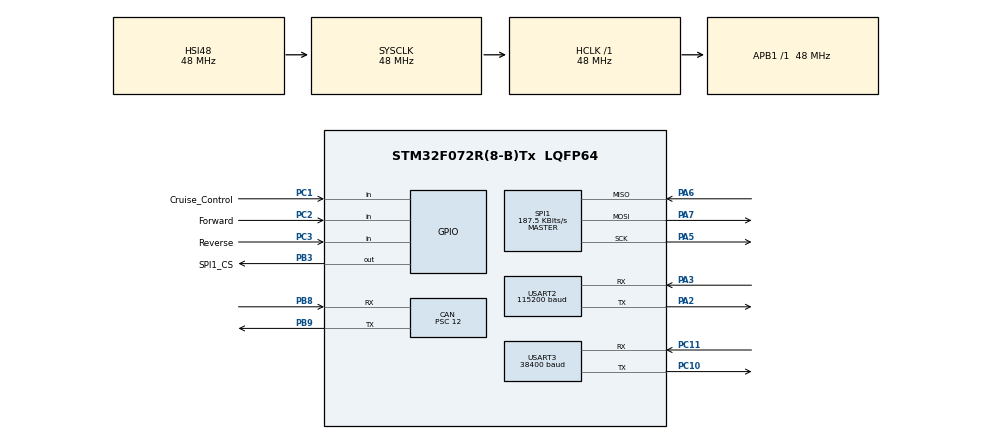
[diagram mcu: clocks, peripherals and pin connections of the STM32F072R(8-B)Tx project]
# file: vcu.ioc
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CAN.BS1=CAN_BS1_13TQ
CAN.BS2=CAN_BS2_2TQ
CAN.CalculateBaudRate=250000
CAN.CalculateTimeBit=4000
CAN.CalculateTimeQuantum=250.0
CAN.Prescaler=12
Mcu.Family=STM32F0
Mcu.Name=STM32F072R(8-B)Tx
Mcu.Package=LQFP64
PA2.Mode=Asynchronous
PA2.Signal=USART2_TX
PA3.Mode=Asynchronous
PA3.Signal=USART2_RX
PA5.Mode=Full_Duplex_Master
PA5.Signal=SPI1_SCK
PA6.Mode=Full_Duplex_Master
PA6.Signal=SPI1_MISO
PA7.Mode=Full_Duplex_Master
PA7.Signal=SPI1_MOSI
PB3.GPIO_Label=SPI1_CS
PB3.Signal=GPIO_Output
PB8.Mode=CAN_Activate
PB8.Signal=CAN_RX
PB9.Mode=CAN_Activate
PB9.Signal=CAN_TX
PC1.GPIO_Label=Cruise_Control
PC1.GPIO_PuPd=GPIO_PULLUP
PC1.Signal=GPIO_Input
PC10.Mode=Asynchronous
PC10.Signal=USART3_TX
PC11.Mode=Asynchronous
PC11.Signal=USART3_RX
PC2.GPIO_Label=Forward
PC2.GPIO_PuPd=GPIO_PULLUP
PC2.Signal=GPIO_Input
PC3.GPIO_Label=Reverse
PC3.GPIO_PuPd=GPIO_PULLUP
PC3.Signal=GPIO_Input
PF0-OSC_IN.Mode=HSE-External-Oscillator
PF0-OSC_IN.Signal=RCC_OSC_IN
PF1-OSC_OUT.Mode=HSE-External-Oscillator
PF1-OSC_OUT.Signal=RCC_OSC_OUT
ProjectManager.HeapSize=0x200
ProjectManager.StackSize=0x400
ProjectManager.TargetToolchain=STM32CubeIDE
RCC.AHBFreq_Value=48000000
RCC.APB1Freq_Value=48000000
RCC.APB1TimFreq_Value=48000000
RCC.HCLKFreq_Value=48000000
RCC.PLLSourceVirtual=RCC_PLLSOURCE_HSI48
RCC.SYSCLKFreq_VALUE=48000000
RCC.SYSCLKSource=RCC_SYSCLKSOURCE_HSI48
SPI1.BaudRatePrescaler=SPI_BAUDRATEPRESCALER_256
SPI1.CLKPolarity=SPI_POLARITY_LOW
SPI1.CalculateBaudRate=187.5 KBits/s
SPI1.DataSize=SPI_DATASIZE_8BIT
SPI1.Direction=SPI_DIRECTION_2LINES
SPI1.Mode=SPI_MODE_MASTER
SPI1.VirtualType=VM_MASTER
TIM16.Period=249
TIM16.Prescaler=47999
TIM6.Period=499
TIM6.Prescaler=47
TIM7.Period=39
TIM7.Prescaler=47999
USART2.BaudRate=115200
USART2.VirtualMode-Asynchronous=VM_ASYNC
USART3.BaudRate=38400
USART3.SwapParam=ADVFEATURE_SWAP_DISABLE
USART3.VirtualMode-Asynchronous=VM_ASYNC
VP_TIM16_VS_ClockSourceINT.Mode=Enable_Timer
VP_TIM3_VS_ClockSourceINT.Mode=Internal
VP_TIM6_VS_ClockSourceINT.Mode=Enable_Timer
VP_TIM7_VS_ClockSourceINT.Mode=Enable_Timer
board=custom

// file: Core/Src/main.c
/* USER CODE BEGIN Header */
/**
  ******************************************************************************
  * @file           : main.c
  * @brief          : Main program body
  ******************************************************************************
  * @attention
  *
  * Copyright (c) 2023 STMicroelectronics.
  * All rights reserved.
  *
  * This software is licensed under terms that can be found in the LICENSE file
  * in the root directory of this software component.
  * If no LICENSE file comes with this software, it is provided AS-IS.
  *
  ******************************************************************************
  */
/* USER CODE END Header */
#include "main.h"

/* USER CODE BEGIN Includes */
#include "run.h"
/* USER CODE END Includes */

CAN_HandleTypeDef hcan;

SPI_HandleTypeDef hspi1;

TIM_HandleTypeDef htim3;
TIM_HandleTypeDef htim6;
TIM_HandleTypeDef htim7;
TIM_HandleTypeDef htim16;

UART_HandleTypeDef huart2;
UART_HandleTypeDef huart3;

void SystemClock_Config(void);
static void MX_GPIO_Init(void);
static void MX_SPI1_Init(void);
static void MX_USART2_UART_Init(void);
static void MX_CAN_Init(void);
static void MX_TIM3_Init(void);
static void MX_USART3_UART_Init(void);
static void MX_TIM7_Init(void);
static void MX_TIM6_Init(void);
static void MX_TIM16_Init(void);

int main(void)
{

  /* MCU Configuration--------------------------------------------------------*/

  /* Reset of all peripherals, Initializes the Flash interface and the Systick. */
  HAL_Init();

  /* Configure the system clock */
  SystemClock_Config();

  /* Initialize all configured peripherals */
  MX_GPIO_Init();
  MX_SPI1_Init();
  MX_USART2_UART_Init();
  MX_CAN_Init();
  MX_TIM3_Init();
  MX_USART3_UART_Init();
  MX_TIM7_Init();
  MX_TIM6_Init();
  MX_TIM16_Init();
  /* USER CODE BEGIN 2 */
  run(&htim3, &hcan, &hspi1, &huart2, &huart3, &htim7, &htim6, &htim16);
  /* USER CODE END 2 */

  /* Infinite loop */
  while (1)
  {

  }
}

void SystemClock_Config(void)
{
  RCC_OscInitTypeDef RCC_OscInitStruct = {0};
  RCC_ClkInitTypeDef RCC_ClkInitStruct = {0};
  RCC_PeriphCLKInitTypeDef PeriphClkInit = {0};

  /** Initializes the RCC Oscillators according to the specified parameters
  * in the RCC_OscInitTypeDef structure.
  */
  RCC_OscInitStruct.OscillatorType = RCC_OSCILLATORTYPE_HSI48;
  RCC_OscInitStruct.HSI48State = RCC_HSI48_ON;
  RCC_OscInitStruct.PLL.PLLState = RCC_PLL_NONE;
  if (HAL_RCC_OscConfig(&RCC_OscInitStruct) != HAL_OK)
  {
    Error_Handler();
  }

  /** Initializes the CPU, AHB and APB buses clocks
  */
  RCC_ClkInitStruct.ClockType = RCC_CLOCKTYPE_HCLK|RCC_CLOCKTYPE_SYSCLK
                              |RCC_CLOCKTYPE_PCLK1;
  RCC_ClkInitStruct.SYSCLKSource = RCC_SYSCLKSOURCE_HSI48;
  RCC_ClkInitStruct.AHBCLKDivider = RCC_SYSCLK_DIV1;
  RCC_ClkInitStruct.APB1CLKDivider = RCC_HCLK_DIV1;

  if (HAL_RCC_ClockConfig(&RCC_ClkInitStruct, FLASH_LATENCY_1) != HAL_OK)
  {
    Error_Handler();
  }
  PeriphClkInit.PeriphClockSelection = RCC_PERIPHCLK_USART2;
  PeriphClkInit.Usart2ClockSelection = RCC_USART2CLKSOURCE_PCLK1;
  if (HAL_RCCEx_PeriphCLKConfig(&PeriphClkInit) != HAL_OK)
  {
    Error_Handler();
  }
}

static void MX_CAN_Init(void)
{

  hcan.Instance = CAN;
  hcan.Init.Prescaler = 12;
  hcan.Init.Mode = CAN_MODE_NORMAL;
  hcan.Init.SyncJumpWidth = CAN_SJW_1TQ;
  hcan.Init.TimeSeg1 = CAN_BS1_13TQ;
  hcan.Init.TimeSeg2 = CAN_BS2_2TQ;
  hcan.Init.TimeTriggeredMode = DISABLE;
  hcan.Init.AutoBusOff = DISABLE;
  hcan.Init.AutoWakeUp = DISABLE;
  hcan.Init.AutoRetransmission = DISABLE;
  hcan.Init.ReceiveFifoLocked = DISABLE;
  hcan.Init.TransmitFifoPriority = DISABLE;
  if (HAL_CAN_Init(&hcan) != HAL_OK)
  {
    Error_Handler();
  }

}

static void MX_SPI1_Init(void)
{

  /* SPI1 parameter configuration*/
  hspi1.Instance = SPI1;
  hspi1.Init.Mode = SPI_MODE_MASTER;
  hspi1.Init.Direction = SPI_DIRECTION_2LINES;
  hspi1.Init.DataSize = SPI_DATASIZE_8BIT;
  hspi1.Init.CLKPolarity = SPI_POLARITY_LOW;
  hspi1.Init.CLKPhase = SPI_PHASE_1EDGE;
  hspi1.Init.NSS = SPI_NSS_SOFT;
  hspi1.Init.BaudRatePrescaler = SPI_BAUDRATEPRESCALER_256;
  hspi1.Init.FirstBit = SPI_FIRSTBIT_MSB;
  hspi1.Init.TIMode = SPI_TIMODE_DISABLE;
  hspi1.Init.CRCCalculation = SPI_CRCCALCULATION_DISABLE;
  hspi1.Init.CRCPolynomial = 7;
  hspi1.Init.CRCLength = SPI_CRC_LENGTH_DATASIZE;
  hspi1.Init.NSSPMode = SPI_NSS_PULSE_ENABLE;
  if (HAL_SPI_Init(&hspi1) != HAL_OK)
  {
    Error_Handler();
  }

}

static void MX_TIM3_Init(void)
{

  TIM_ClockConfigTypeDef sClockSourceConfig = {0};
  TIM_MasterConfigTypeDef sMasterConfig = {0};

  htim3.Instance = TIM3;
  htim3.Init.Prescaler = 0;
  htim3.Init.CounterMode = TIM_COUNTERMODE_UP;
  htim3.Init.Period = 65535;
  htim3.Init.ClockDivision = TIM_CLOCKDIVISION_DIV1;
  htim3.Init.AutoReloadPreload = TIM_AUTORELOAD_PRELOAD_DISABLE;
  if (HAL_TIM_Base_Init(&htim3) != HAL_OK)
  {
    Error_Handler();
  }
  sClockSourceConfig.ClockSource = TIM_CLOCKSOURCE_INTERNAL;
  if (HAL_TIM_ConfigClockSource(&htim3, &sClockSourceConfig) != HAL_OK)
  {
    Error_Handler();
  }
  sMasterConfig.MasterOutputTrigger = TIM_TRGO_RESET;
  sMasterConfig.MasterSlaveMode = TIM_MASTERSLAVEMODE_DISABLE;
  if (HAL_TIMEx_MasterConfigSynchronization(&htim3, &sMasterConfig) != HAL_OK)
  {
    Error_Handler();
  }

}

static void MX_TIM6_Init(void)
{

  TIM_MasterConfigTypeDef sMasterConfig = {0};

  htim6.Instance = TIM6;
  htim6.Init.Prescaler = 47;
  htim6.Init.CounterMode = TIM_COUNTERMODE_UP;
  htim6.Init.Period = 499;
  htim6.Init.AutoReloadPreload = TIM_AUTORELOAD_PRELOAD_DISABLE;
  if (HAL_TIM_Base_Init(&htim6) != HAL_OK)
  {
    Error_Handler();
  }
  sMasterConfig.MasterOutputTrigger = TIM_TRGO_RESET;
  sMasterConfig.MasterSlaveMode = TIM_MASTERSLAVEMODE_DISABLE;
  if (HAL_TIMEx_MasterConfigSynchronization(&htim6, &sMasterConfig) != HAL_OK)
  {
    Error_Handler();
  }

}

static void MX_TIM7_Init(void)
{

  TIM_MasterConfigTypeDef sMasterConfig = {0};

  htim7.Instance = TIM7;
  htim7.Init.Prescaler = 47999;
  htim7.Init.CounterMode = TIM_COUNTERMODE_UP;
  htim7.Init.Period = 39;
  htim7.Init.AutoReloadPreload = TIM_AUTORELOAD_PRELOAD_DISABLE;
  if (HAL_TIM_Base_Init(&htim7) != HAL_OK)
  {
    Error_Handler();
  }
  sMasterConfig.MasterOutputTrigger = TIM_TRGO_RESET;
  sMasterConfig.MasterSlaveMode = TIM_MASTERSLAVEMODE_DISABLE;
  if (HAL_TIMEx_MasterConfigSynchronization(&htim7, &sMasterConfig) != HAL_OK)
  {
    Error_Handler();
  }

}

static void MX_TIM16_Init(void)
{

  htim16.Instance = TIM16;
  htim16.Init.Prescaler = 47999;
  htim16.Init.CounterMode = TIM_COUNTERMODE_UP;
  htim16.Init.Period = 249;
  htim16.Init.ClockDivision = TIM_CLOCKDIVISION_DIV1;
  htim16.Init.RepetitionCounter = 0;
  htim16.Init.AutoReloadPreload = TIM_AUTORELOAD_PRELOAD_DISABLE;
  if (HAL_TIM_Base_Init(&htim16) != HAL_OK)
  {
    Error_Handler();
  }

}

static void MX_USART2_UART_Init(void)
{

  huart2.Instance = USART2;
  huart2.Init.BaudRate = 115200;
  huart2.Init.WordLength = UART_WORDLENGTH_8B;
  huart2.Init.StopBits = UART_STOPBITS_1;
  huart2.Init.Parity = UART_PARITY_NONE;
  huart2.Init.Mode = UART_MODE_TX_RX;
  huart2.Init.HwFlowCtl = UART_HWCONTROL_NONE;
  huart2.Init.OverSampling = UART_OVERSAMPLING_16;
  huart2.Init.OneBitSampling = UART_ONE_BIT_SAMPLE_DISABLE;
  huart2.AdvancedInit.AdvFeatureInit = UART_ADVFEATURE_NO_INIT;
  if (HAL_UART_Init(&huart2) != HAL_OK)
  {
    Error_Handler();
  }

}

static void MX_USART3_UART_Init(void)
{

  huart3.Instance = USART3;
  huart3.Init.BaudRate = 38400;
  huart3.Init.WordLength = UART_WORDLENGTH_8B;
  huart3.Init.StopBits = UART_STOPBITS_1;
  huart3.Init.Parity = UART_PARITY_NONE;
  huart3.Init.Mode = UART_MODE_TX_RX;
  huart3.Init.HwFlowCtl = UART_HWCONTROL_NONE;
  huart3.Init.OverSampling = UART_OVERSAMPLING_16;
  huart3.Init.OneBitSampling = UART_ONE_BIT_SAMPLE_DISABLE;
  huart3.AdvancedInit.AdvFeatureInit = UART_ADVFEATURE_NO_INIT;
  if (HAL_UART_Init(&huart3) != HAL_OK)
  {
    Error_Handler();
  }

}

static void MX_GPIO_Init(void)
{
  GPIO_InitTypeDef GPIO_InitStruct = {0};

  /* GPIO Ports Clock Enable */
  __HAL_RCC_GPIOF_CLK_ENABLE();
  __HAL_RCC_GPIOC_CLK_ENABLE();
  __HAL_RCC_GPIOA_CLK_ENABLE();
  __HAL_RCC_GPIOB_CLK_ENABLE();

  /*Configure GPIO pin Output Level */
  HAL_GPIO_WritePin(SPI1_CS_GPIO_Port, SPI1_CS_Pin, GPIO_PIN_RESET);

  /*Configure GPIO pins : Cruise_Control_Pin Forward_Pin Reverse_Pin */
  GPIO_InitStruct.Pin = Cruise_Control_Pin|Forward_Pin|Reverse_Pin;
  GPIO_InitStruct.Mode = GPIO_MODE_INPUT;
  GPIO_InitStruct.Pull = GPIO_PULLUP;
  HAL_GPIO_Init(GPIOC, &GPIO_InitStruct);

  /*Configure GPIO pin : SPI1_CS_Pin */
  GPIO_InitStruct.Pin = SPI1_CS_Pin;
  GPIO_InitStruct.Mode = GPIO_MODE_OUTPUT_PP;
  GPIO_InitStruct.Pull = GPIO_NOPULL;
  GPIO_InitStruct.Speed = GPIO_SPEED_FREQ_LOW;
  HAL_GPIO_Init(SPI1_CS_GPIO_Port, &GPIO_InitStruct);

}

void Error_Handler(void)
{
  __disable_irq();
  while (1)
  {
  }
}
